# ATSAMRH71F20C register map
Vendor: Microchip Technology; Series: SAMRH71; File version: 0
CPU: CM7 r1p1, little endian, MPU, FPU, 3 interrupt priority bits
Registers are 32-bit, read-write, reset 0x0 unless marked. A register's access mark holds for its fields unless they carry their own. Offsets are from the block's base; [hi:lo] are bit positions; {n}, {i} and the like mark numbered series.

## TRNG — True Random Number Generator
Base 0x40090000; register names take the prefix TRNG_
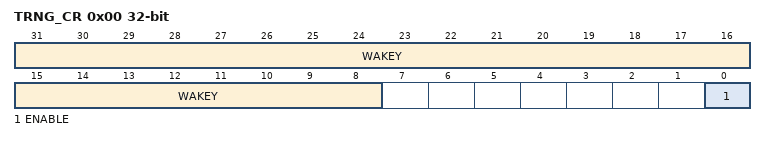
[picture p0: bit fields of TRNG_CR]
0x00 TRNG_CR wo — Control Register
  [31:8] WAKEY — Register Write Access Key
    0x524E47=PASSWD (Writing any other value in this field aborts the write operation.)
  [0] ENABLE — Enables the TRNG to Provide Random Values
0x10 TRNG_IER wo — Interrupt Enable Register
  [0] DATRDY — Data Ready Interrupt Enable
0x14 TRNG_IDR wo — Interrupt Disable Register
  [0] DATRDY — Data Ready Interrupt Disable
0x18 TRNG_IMR ro — Interrupt Mask Register
  [0] DATRDY — Data Ready Interrupt Mask
0x1C TRNG_ISR ro — Interrupt Status Register
  [0] DATRDY — Data Ready (cleared on read)
0x50 TRNG_ODATA ro — Output Data Register
  [31:0] ODATA — Output Data

## WDT — Watchdog Timer
Base 0x40100250; register names take the prefix WDT_
Same registers: WDT1 0x40100300
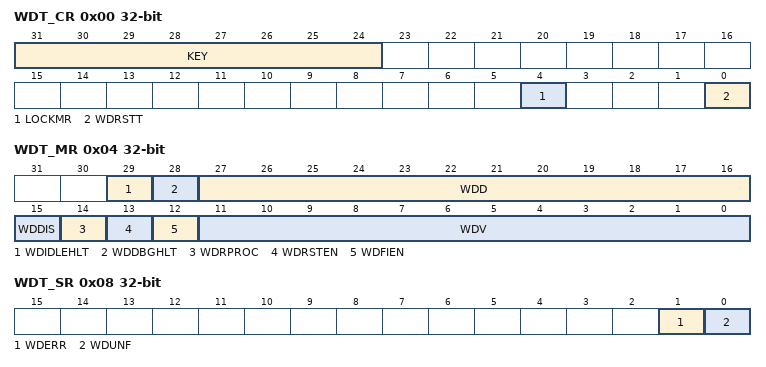
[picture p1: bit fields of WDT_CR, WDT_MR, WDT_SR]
0x00 WDT_CR wo — Control Register
  [31:24] KEY — Password
    165=PASSWD (Writing any other value in this field aborts the write operation.)
  [4] LOCKMR — Lock Mode Register Write Access
  [0] WDRSTT — Watchdog Restart
0x04 WDT_MR — Mode Register
  [29] WDIDLEHLT — Watchdog Idle Halt
  [28] WDDBGHLT — Watchdog Debug Halt
  [27:16] WDD — Watchdog Delta Value
  [15] WDDIS — Watchdog Disable
  [14] WDRPROC — Watchdog Reset Processor
  [13] WDRSTEN — Watchdog Reset Enable
  [12] WDFIEN — Watchdog Fault Interrupt Enable
  [11:0] WDV — Watchdog Counter Value
0x08 WDT_SR ro — Status Register
  [1] WDERR — Watchdog Error (cleared on read)
  [0] WDUNF — Watchdog Underflow (cleared on read)

## LOCKBIT
Base 0x00000000; register names take the prefix LOCKBIT_
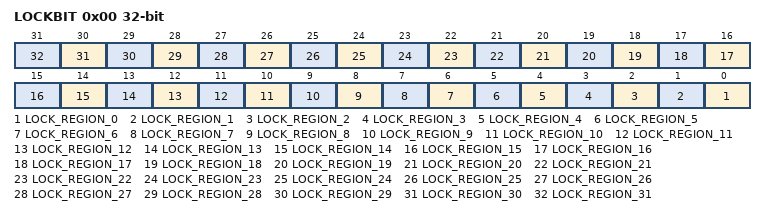
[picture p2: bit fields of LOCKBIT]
0x00 LOCKBIT — Lock Bits
  [n] LOCK_REGION_{n} (n=0..31)

## SCnSCB — System control not in SCB
Base 0xE000E000; register names take the prefix SCnSCB_
0x04 ICTR ro — Interrupt Controller Type Register
  [3:0] INTLINESNUM — Total number of interrupt lines supported by an implementation, defined in groups of 32
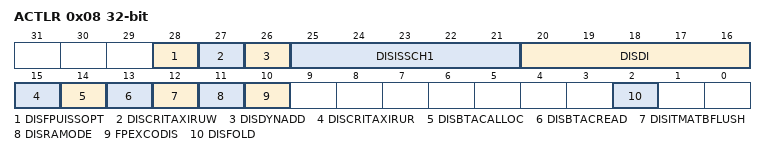
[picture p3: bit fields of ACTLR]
0x08 ACTLR — Auxiliary Control Register
  [28] DISFPUISSOPT — Disables dynamic allocation of ADD and SUB instructions
  [27] DISCRITAXIRUW — Disable critical AXI read-under-write
  [26] DISDYNADD — Disables dynamic allocation of ADD and SUB instructions
  [25:21] DISISSCH1
  [20:16] DISDI
  [15] DISCRITAXIRUR
  [14] DISBTACALLOC
  [13] DISBTACREAD
  [12] DISITMATBFLUSH — Disables ITM and DWT ATB flush
  [11] DISRAMODE — Disables dynamic read allocate mode for Write-Back Write-Allocate memory regions
  [10] FPEXCODIS — Disables FPU exception outputs
  [2] DISFOLD — Disables folding of IT instructions

## SysTick — System timer
Base 0xE000E010; register names take the prefix SysTick_
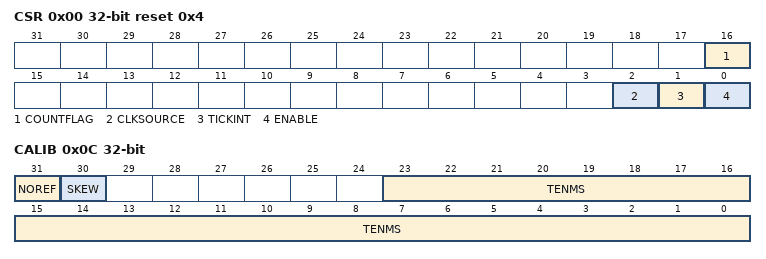
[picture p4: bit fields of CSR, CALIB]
0x00 CSR reset 0x4 — Control and Status Register
  [16] COUNTFLAG — Returns 1 if timer counted to 0 since last time this was read
  [2] CLKSOURCE — Indicates the clock source
    0=external clock; 1=processor clock
  [1] TICKINT — Enables SysTick exception request
    0=counting down to 0 does not assert the SysTick exception request; 1=counting down to 0 asserts the SysTick exception request
  [0] ENABLE — Enables the counter
    0=counter disabled; 1=counter enabled
0x04 RVR — Reload Value Register
  [23:0] RELOAD — Value to load into the SysTick Current Value Register when the counter reaches 0
0x08 CVR — Current Value Register
  [23:0] CURRENT — Current value at the time the register is accessed
0x0C CALIB ro — Calibration Value Register
  [31] NOREF — Indicates whether the device provides a reference clock to the processor
    0=The reference clock is provided; 1=The reference clock is not provided
  [30] SKEW — Indicates whether the TENMS value is exact
    0=10ms calibration value is exact; 1=10ms calibration value is inexact, because of the clock frequency
  [23:0] TENMS — Reload value to use for 10ms timing
